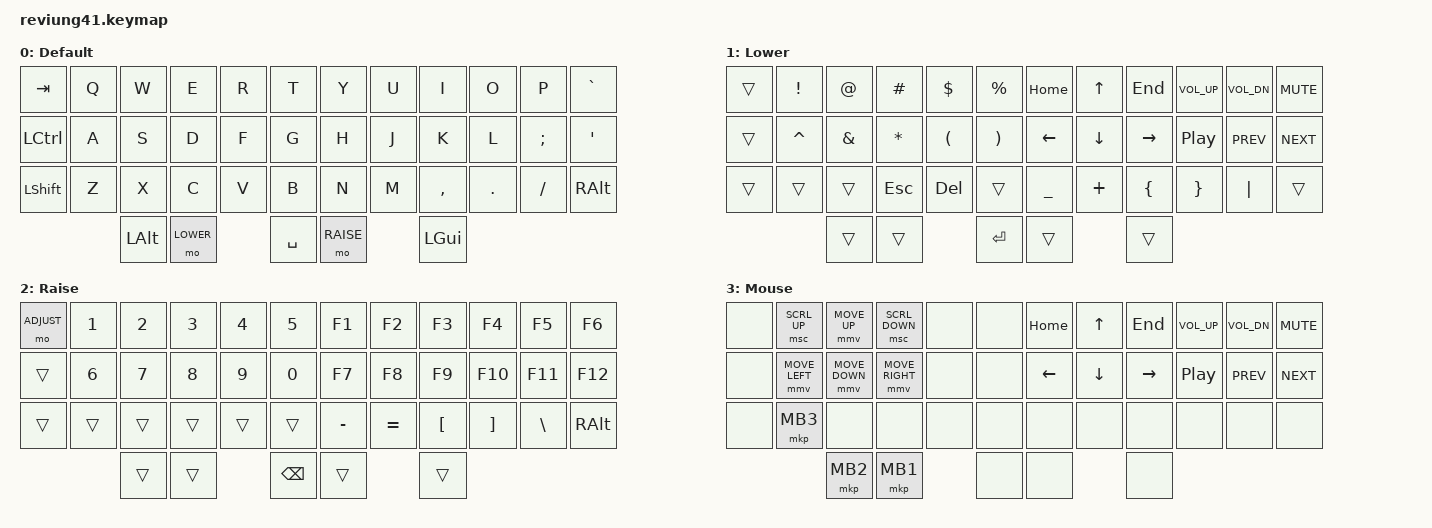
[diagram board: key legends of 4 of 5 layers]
/*
 * Copyright (c) 2020 The ZMK Contributors
 *
 * SPDX-License-Identifier: MIT
 */

#include <behaviors.dtsi>
#include <dt-bindings/zmk/keys.h>
#include <dt-bindings/zmk/bt.h>
#include <dt-bindings/zmk/rgb.h>
#include <dt-bindings/zmk/mouse.h>
#include <dt-bindings/zmk/pointing.h>

#define DEFAULT 0
#define LOWER   1
#define RAISE   2
#define MOUSE 3
#define ADJUST  4

#define ZMK_POINTING_DEFAULT_MOVE_VAL 1500
#define ZMK_POINTING_DEFAULT_SCRL_VAL 200

/ {
    combos {
        compatible = "zmk,combos";

        combo_space {
            timeout-ms = <25>;
            key-positions = <19 20>;
            bindings = <&kp SPACE>;
        };

        combo_undo {
            timeout-ms = <25>;
            key-positions = <26 27>; 
            bindings = <&kp LC(Z)>;
        };

        combo_mouse_mode {
            timeout-ms = <25>;
            key-positions = <8 9 10 11>;
            bindings = <&tog MOUSE>;
        };
    };

    keymap {
        compatible = "zmk,keymap";

        default_layer {
            display-name = "Default";
            bindings = <
&kp TAB   &kp Q &kp W &kp E &kp R &kp T   &kp Y &kp U  &kp I   &kp O    &kp P    &kp GRAVE
&kp LCTRL &kp A &kp S &kp D &kp F &kp G   &kp H &kp J  &kp K   &kp L    &kp SEMI &kp SQT
&kp LSHFT &kp Z &kp X &kp C &kp V &kp B   &kp N &kp M  &kp COMMA &kp DOT  &kp FSLH &kp RALT
                &kp LALT &mo LOWER &kp SPACE &mo RAISE &kp LGUI
            >;
        };

        lower_layer {
            display-name = "Lower";
            bindings = <
&trans &kp EXCL  &kp AT    &kp HASH &kp DLLR &kp PRCNT    &kp HOME  &kp UP    &kp END   &kp C_VOL_UP &kp C_VOL_DN &kp C_MUTE
&trans &kp CARET &kp AMPS  &kp ASTRK &kp LPAR &kp RPAR    &kp LEFT  &kp DOWN  &kp RIGHT &kp C_PP     &kp C_PREV   &kp C_NEXT
&trans &trans    &trans    &kp ESC  &kp DEL  &trans       &kp UNDER &kp PLUS  &kp LBRC  &kp RBRC     &kp PIPE     &trans
                                    &trans &trans &kp RET &trans &trans
            >;
        };

        raise_layer {
            display-name = "Raise";
            bindings = <
&mo ADJUST &kp N1 &kp N2 &kp N3 &kp N4 &kp N5    &kp F1    &kp F2    &kp F3    &kp F4    &kp F5   &kp F6
&trans     &kp N6 &kp N7 &kp N8 &kp N9 &kp N0    &kp F7    &kp F8    &kp F9    &kp F10   &kp F11  &kp F12
&trans     &trans &trans &trans &trans &trans    &kp MINUS &kp EQUAL &kp LBKT  &kp RBKT  &kp BSLH &kp RALT
                    &trans &trans &kp BSPC &trans &trans
            >;
        };

        mouse_layer {
            display-name = "Mouse";
            bindings = <
&none &msc SCRL_UP &mmv MOVE_UP  &msc SCRL_DOWN &none &none   &kp HOME  &kp UP    &kp END   &kp C_VOL_UP &kp C_VOL_DN &kp C_MUTE
&none &mmv MOVE_LEFT &mmv MOVE_DOWN &mmv MOVE_RIGHT &none &none &kp LEFT  &kp DOWN  &kp RIGHT &kp C_PP     &kp C_PREV   &kp C_NEXT
&none &mkp MB3 &none &none &none &none   &none &none &none &none &none &none
                    &mkp MB2 &mkp MB1 &none &none &none
            >;
        };

        adjust_layer {
            display-name = "Adjust";
            bindings = <
&none &bt BT_SEL 1 &bt BT_SEL 2 &bt BT_SEL 3 &bt BT_SEL 4 &none           &none       &none &none &none &none &sys_reset
&none &none &none &none &none &bt BT_SEL 0       &none &none &none &none &none
&none &none &none &bt BT_CLR_ALL &bt BT_CLR &none           &none  &none &none &none &none &none
                                        &none &none &none &none &none
            >;
        };
    };
};

/*
empty keymap preset:
&none &none &none &none &none &none   &none &none &none &none &none &none
&none &none &none &none &none &none   &none &none &none &none &none &none
&none &none &none &none &none &none   &none &none &none &none &none &none
                    &none &none &none &none &none
*/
